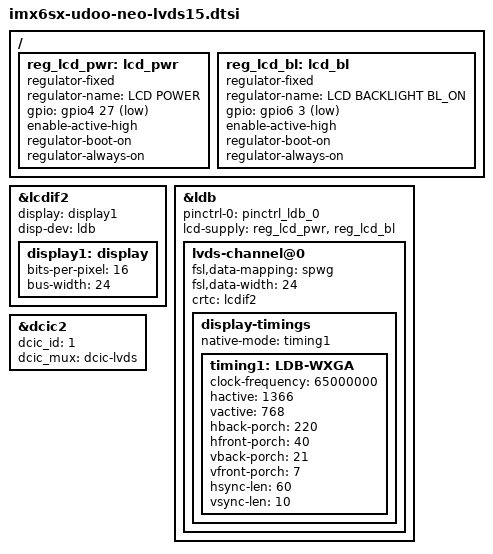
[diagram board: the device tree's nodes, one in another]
/*
 * Copyright (C) 2015 Jasbir Matharu
 * Author: Ettore Chimenti <ek5.chimenti@gmail.com>
 *
 * This program is free software; you can redistribute it and/or modify
 * it under the terms of the GNU General Public License version 2 as
 * published by the Free Software Foundation.
 */

/ {
	reg_lcd_pwr: lcd_pwr {
		compatible = "regulator-fixed";
		regulator-name = "LCD POWER";
		gpio = <&gpio4 27 GPIO_ACTIVE_LOW>;
		enable-active-high;
		regulator-boot-on;
		regulator-always-on;
		status = "okay";
	};

	reg_lcd_bl: lcd_bl {
		compatible = "regulator-fixed";
		regulator-name = "LCD BACKLIGHT BL_ON";
		gpio = <&gpio6 3 GPIO_ACTIVE_LOW>;
		enable-active-high;
		regulator-boot-on;
		regulator-always-on;
	};
};

&lcdif2 {
	display = <&display1>;
	disp-dev = "ldb";
	status = "okay";

	display1: display {
		bits-per-pixel = <16>;
		bus-width = <24>;
	};
};

&ldb {
	pinctrl-names = "default";
	pinctrl-0 = <&pinctrl_ldb_0>;
	lcd-supply = <&reg_lcd_pwr 
                      &reg_lcd_bl>;
	status = "okay";

	lvds-channel@0 {
		fsl,data-mapping = "spwg";
		fsl,data-width = <24>;
		crtc = "lcdif2";
		status = "okay";
		
		display-timings {
			native-mode = <&timing1>;
			timing1: LDB-WXGA {
				clock-frequency = <65000000>;
				hactive = <1366>;
				vactive = <768>;
				hback-porch = <220>;
				hfront-porch = <40>;
				vback-porch = <21>;
				vfront-porch = <7>;
				hsync-len = <60>;
				vsync-len = <10>;
			};
		};
	};
};

&dcic2 {
	dcic_id = <1>;
	dcic_mux = "dcic-lvds";
	status = "okay";
};
